AUTOSAR XML (schema 00045)
package /Cpr
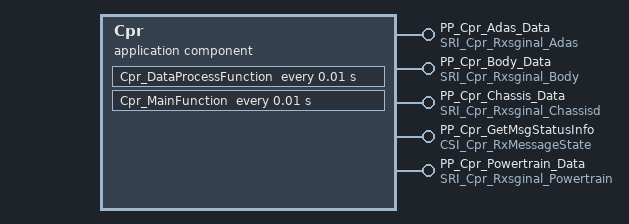
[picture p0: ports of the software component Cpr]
  application sw component type Cpr
    5 x provide port:
      PP_Cpr_Adas_Data: provided-interface=SRI_Cpr_Rxsginal_Adas
      PP_Cpr_Body_Data: provided-interface=SRI_Cpr_Rxsginal_Body
      PP_Cpr_Chassis_Data: provided-interface=SRI_Cpr_Rxsginal_Chassisd
      PP_Cpr_GetMsgStatusInfo: provided-interface=CSI_Cpr_RxMessageState
      PP_Cpr_Powertrain_Data: provided-interface=SRI_Cpr_Rxsginal_Powertrain
    behavior Cpr_IB: handle-termination-and-restart=NO-SUPPORT
      operation invoked event Get_RxMsgStatus_Event: start-on-event=Get_RxMsgStatus, operation=PP_Cpr_GetMsgStatusInfo.Get_RxMsgStatus
      init event InitEvent_Cpr_InitFunction: start-on-event=Cpr_InitFunction
      timing event TimingEvent_Cpr_DataProcessFunction: start-on-event=Cpr_DataProcessFunction, period=0.01
      timing event TimingEvent_Cpr_MainFunction: start-on-event=Cpr_MainFunction, period=0.01
      4 x runnable:
        Cpr_DataProcessFunction
        Cpr_InitFunction
        Cpr_MainFunction
          data-send-points:
            252 x access:
              dsp_ACCMode: accessed-variable=PP_Cpr_Adas_Data.ACCMode
              dsp_ACCMode_Status: accessed-variable=PP_Cpr_Adas_Data.ACCMode_Status
              dsp_ACC_HostLaneLeftStatus: accessed-variable=PP_Cpr_Body_Data.ACC_HostLaneLeftStatus
              dsp_ACC_HostLaneRightStatus: accessed-variable=PP_Cpr_Body_Data.ACC_HostLaneRightStatus
              dsp_ACC_IACCHWAMode: accessed-variable=PP_Cpr_Body_Data.AccIaccHWAMode
              dsp_AccIaccHWAMode_Status: accessed-variable=PP_Cpr_Body_Data.AccIaccHWAMode_Status
              dsp_AdsUDLCStatus: accessed-variable=PP_Cpr_Chassis_Data.AdsUDLCStatus
              dsp_AdsUDLCStatus_Status: accessed-variable=PP_Cpr_Chassis_Data.AdsUDLCStatus_Status
              dsp_BCM_BrakeLampError: accessed-variable=PP_Cpr_Body_Data.BCM_BrakeLampError
              dsp_BCM_BrakeLampError_Status: accessed-variable=PP_Cpr_Body_Data.BCM_BrakeLampError_Status
              dsp_BCM_TurnLightSwitchSts: accessed-variable=PP_Cpr_Body_Data.BCM_TurnLightSwitchSts
              dsp_BCM_TurnLightSwitchSts_S: accessed-variable=PP_Cpr_Body_Data.BCM_TurnLightSwitchSts_Status
              dsp_BcmAutHeadLiSts: accessed-variable=PP_Cpr_Body_Data.BcmAutHeadLiSts
              dsp_BcmAutHeadLiSts_Status: accessed-variable=PP_Cpr_Body_Data.BcmAutHeadLiSts_Status
              dsp_BcmDrvrDoorSts: accessed-variable=PP_Cpr_Body_Data.BcmDrvrDoorSts
              dsp_BcmDrvrDoorSts_Status: accessed-variable=PP_Cpr_Body_Data.BcmDrvrDoorSts_Status
              dsp_BcmEmgyLiSts: accessed-variable=PP_Cpr_Body_Data.BcmEmgyLiSts
              dsp_BcmEmgyLiSts_Status: accessed-variable=PP_Cpr_Body_Data.BcmEmgyLiSts_Status
              dsp_BcmFrntFogLmpSts: accessed-variable=PP_Cpr_Body_Data.BcmFrntFogLmpSts
              dsp_BcmFrntFogLmpSts_Status: accessed-variable=PP_Cpr_Body_Data.BcmFrntFogLmpSts_Status
              dsp_BcmFrntWiperSts: accessed-variable=PP_Cpr_Body_Data.BcmFrntWiperSts
              dsp_BcmFrntWiperSts_Status: accessed-variable=PP_Cpr_Body_Data.BcmFrntWiperSts_Status
              dsp_BcmHiBeamSts: accessed-variable=PP_Cpr_Body_Data.BcmHiBeamSts
              dsp_BcmHiBeamSts_Status: accessed-variable=PP_Cpr_Body_Data.BcmHiBeamSts_Status
              dsp_BcmLeReDoorSts: accessed-variable=PP_Cpr_Body_Data.BcmLeReDoorSts
              dsp_BcmLeReDoorSts_Status: accessed-variable=PP_Cpr_Body_Data.BcmLeReDoorSts_Status
              dsp_BcmLoBeamSts: accessed-variable=PP_Cpr_Body_Data.BcmLoBeamSts
              dsp_BcmLoBeamSts_Status: accessed-variable=PP_Cpr_Body_Data.BcmLoBeamSts_Status
              dsp_BcmPassDoorSts: accessed-variable=PP_Cpr_Body_Data.BcmPassDoorSts
              dsp_BcmPassDoorSts_Status: accessed-variable=PP_Cpr_Body_Data.BcmPassDoorSts_Status
              dsp_BcmReFoglmpSts: accessed-variable=PP_Cpr_Body_Data.BcmReFoglmpSts
              dsp_BcmReFoglmpSts_Status: accessed-variable=PP_Cpr_Body_Data.BcmReFoglmpSts_Status
              dsp_BcmRiReDoorSts: accessed-variable=PP_Cpr_Body_Data.BcmRiReDoorSts
              dsp_BcmRiReDoorSts_Status: accessed-variable=PP_Cpr_Body_Data.BcmRiReDoorSts_Status
              dsp_BcmTurnIndcrLe: accessed-variable=PP_Cpr_Body_Data.BcmTurnIndcrLe
              dsp_BcmTurnIndcrLe_Status: accessed-variable=PP_Cpr_Body_Data.BcmTurnIndcrLe_Status
              dsp_BcmTurnIndcrRi: accessed-variable=PP_Cpr_Body_Data.BcmTurnIndcrRi
              dsp_BcmTurnIndcrRi_Status: accessed-variable=PP_Cpr_Body_Data.BcmTurnIndcrRi_Status
              dsp_BrakePressureSimulator: accessed-variable=PP_Cpr_Chassis_Data.BrakePressureSimulator
              dsp_BrakePressureSimulator_S: accessed-variable=PP_Cpr_Chassis_Data.BrakePressureSimulator_Status
              dsp_EPS_APA_EpasFAILED: accessed-variable=PP_Cpr_Chassis_Data.EPS_APA_EpasFAILED
              dsp_EPS_APA_EpasFAILED_Status: accessed-variable=PP_Cpr_Chassis_Data.EPS_APA_EpasFAILED_Status
              dsp_EPS_ActualMotorTorq: accessed-variable=PP_Cpr_Chassis_Data.EPS_ActualMotorTorq
              dsp_EPS_ActualMotorTorq_Stat: accessed-variable=PP_Cpr_Chassis_Data.EPS_ActualMotorTorq_Status
              dsp_EPS_ActualTorsionBarTorq: accessed-variable=PP_Cpr_Chassis_Data.EPS_ActualTorsionBarTorq
              dsp_EPS_ActualTorsionBarTorq0: accessed-variable=PP_Cpr_Chassis_Data.EPS_ActualTorsionBarTorq_Status
              dsp_EPS_MeasuredTorsionBarTo: accessed-variable=PP_Cpr_Chassis_Data.EPS_MeasuredTorsionBarTorqValid
              dsp_EPS_Pinionang_Vali: accessed-variable=PP_Cpr_Chassis_Data.EPS_Pinionang_Valid
              dsp_EPS_fault_state: accessed-variable=PP_Cpr_Chassis_Data.EPS_fault_state
              dsp_EPS_fault_state_Status: accessed-variable=PP_Cpr_Chassis_Data.EPS_fault_state_Status
              dsp_ESP_LatAccelValid: accessed-variable=PP_Cpr_Chassis_Data.ESP_LatAccelValid
              dsp_ESP_LongAccelValid: accessed-variable=PP_Cpr_Chassis_Data.ESP_LongAccelValid
              dsp_ESP_YawRateValid: accessed-variable=PP_Cpr_Chassis_Data.ESP_YawRateValid
              dsp_EpsConcussAvailabilitySt: accessed-variable=PP_Cpr_Chassis_Data.EpsConcussAvailabilityStatus
              dsp_EpsConcussAvailabilitySt0: accessed-variable=PP_Cpr_Chassis_Data.EpsConcussAvailabilityStatus_Status
              dsp_EpsFaild: accessed-variable=PP_Cpr_Chassis_Data.EpsFaild
              dsp_EpsFaild_Status: accessed-variable=PP_Cpr_Chassis_Data.EpsFaild_Status
              dsp_EpsIACCabortreason: accessed-variable=PP_Cpr_Chassis_Data.EpsIACCabortreason
              dsp_EpsIACCabortreason_Status: accessed-variable=PP_Cpr_Chassis_Data.EpsIACCabortreason_Status
              dsp_EpsLatCtrlActive: accessed-variable=PP_Cpr_Chassis_Data.EpsLatCtrlActive
              dsp_EpsLatCtrlActive_Status: accessed-variable=PP_Cpr_Chassis_Data.EpsLatCtrlActive_Status
              dsp_EpsLatCtrlAvailabilitySt: accessed-variable=PP_Cpr_Chassis_Data.EpsLatCtrlAvailabilityStatus
              dsp_EpsLatCtrlAvailabilitySt0: accessed-variable=PP_Cpr_Chassis_Data.EpsLatCtrlAvailabilityStatus_Status
              dsp_EpsMeasuredTorsionBarTor: accessed-variable=PP_Cpr_Chassis_Data.EpsMeasuredTorsionBarTorque
              dsp_EpsMeasuredTorsionBarTor0: accessed-variable=PP_Cpr_Chassis_Data.EpsMeasuredTorsionBarTorq_Status
              dsp_EpsMeasuredTorsionBarTor1: accessed-variable=PP_Cpr_Chassis_Data.EpsMeasuredTorsionBarTorque_Status
              dsp_EpsPinionang: accessed-variable=PP_Cpr_Chassis_Data.EpsPinionang
              dsp_EpsPinionang_Status: accessed-variable=PP_Cpr_Chassis_Data.EpsPinionang_Status
              dsp_EpsSasCalSts: accessed-variable=PP_Cpr_Chassis_Data.EpsSasCalSts
              dsp_EpsSasCalSts_Status: accessed-variable=PP_Cpr_Chassis_Data.EpsSasCalSts_Status
              dsp_EpsSasSteerAg: accessed-variable=PP_Cpr_Chassis_Data.EpsSasSteerAg
              dsp_EpsSasSteerAgVld: accessed-variable=PP_Cpr_Chassis_Data.EpsSasSteerAgVld
              dsp_EpsSasSteerAg_Status: accessed-variable=PP_Cpr_Chassis_Data.EpsSasSteerAg_Status
              dsp_EpsSteerAgRate: accessed-variable=PP_Cpr_Chassis_Data.EpsSteerAgRate
              dsp_EpsSteerAgRate_Status: accessed-variable=PP_Cpr_Chassis_Data.EpsSteerAgRate_Status
              dsp_EpsSteerAgSensFilr: accessed-variable=PP_Cpr_Chassis_Data.EpsSteerAgSensFilr
              dsp_EpsSteerAgSensFilr_Status: accessed-variable=PP_Cpr_Chassis_Data.EpsSteerAgSensFilr_Status
              dsp_EspABAactive: accessed-variable=PP_Cpr_Chassis_Data.EspABAactive
              dsp_EspABAactive_Status: accessed-variable=PP_Cpr_Chassis_Data.EspABAactive_Status
              dsp_EspABAavailable: accessed-variable=PP_Cpr_Chassis_Data.EspABAavailable
              dsp_EspABAavailable_Status: accessed-variable=PP_Cpr_Chassis_Data.EspABAavailable_Status
              dsp_EspAEBAvailable: accessed-variable=PP_Cpr_Chassis_Data.EspAEBAvailable
              dsp_EspAEBAvailable_Status: accessed-variable=PP_Cpr_Chassis_Data.EspAEBAvailable_Status
              dsp_EspAEBdecActive: accessed-variable=PP_Cpr_Chassis_Data.EspAEBdecActive
              dsp_EspAEBdecActive_Status: accessed-variable=PP_Cpr_Chassis_Data.EspAEBdecActive_Status
              dsp_EspAWBactive: accessed-variable=PP_Cpr_Chassis_Data.EspAWBactive
              dsp_EspAWBactive_Status: accessed-variable=PP_Cpr_Chassis_Data.EspAWBactive_Status
              dsp_EspAWBavailable: accessed-variable=PP_Cpr_Chassis_Data.EspAWBavailable
              dsp_EspAWBavailable_Status: accessed-variable=PP_Cpr_Chassis_Data.EspAWBavailable_Status
              dsp_EspAbsActv: accessed-variable=PP_Cpr_Chassis_Data.EspAbsActv
              dsp_EspAbsActv_Status: accessed-variable=PP_Cpr_Chassis_Data.EspAbsActv_Status
              dsp_EspAbsFailr: accessed-variable=PP_Cpr_Chassis_Data.EspAbsFailr
              dsp_EspAbsFailr_Status: accessed-variable=PP_Cpr_Chassis_Data.EspAbsFailr_Status
              dsp_EspActvSts: accessed-variable=PP_Cpr_Chassis_Data.EspActvSts
              dsp_EspActvSts_Status: accessed-variable=PP_Cpr_Chassis_Data.EspActvSts_Status
              dsp_EspEbdFailr: accessed-variable=PP_Cpr_Chassis_Data.EspEbdFailr
              dsp_EspEbdFailr_Status: accessed-variable=PP_Cpr_Chassis_Data.EspEbdFailr_Status
              dsp_EspLatAccel: accessed-variable=PP_Cpr_Chassis_Data.EspLatAccel
              dsp_EspLatAccel_Status: accessed-variable=PP_Cpr_Chassis_Data.EspLatAccel_Status
              dsp_EspLongAccel: accessed-variable=PP_Cpr_Chassis_Data.EspLongAccel
              dsp_EspLongAccel_Status: accessed-variable=PP_Cpr_Chassis_Data.EspLongAccel_Status
              dsp_EspPrefillActive: accessed-variable=PP_Cpr_Chassis_Data.EspPrefillActive
              dsp_EspPrefillActive_Status: accessed-variable=PP_Cpr_Chassis_Data.EspPrefillActive_Status
              dsp_EspPrefillAvailable: accessed-variable=PP_Cpr_Chassis_Data.EspPrefillAvailable
              dsp_EspPrefillAvailable_Stat: accessed-variable=PP_Cpr_Chassis_Data.EspPrefillAvailable_Status
              dsp_EspTcsActvSts: accessed-variable=PP_Cpr_Chassis_Data.EspTcsActvSts
              dsp_EspTcsActvSts_Status: accessed-variable=PP_Cpr_Chassis_Data.EspTcsActvSts_Status
              dsp_EspTcsFailr: accessed-variable=PP_Cpr_Chassis_Data.EspTcsFailr
              dsp_EspTcsFailr_Status: accessed-variable=PP_Cpr_Chassis_Data.EspTcsFailr_Status
              dsp_EspVdcActvSts: accessed-variable=PP_Cpr_Chassis_Data.EspVdcActvSts
              dsp_EspVdcActvSts_Status: accessed-variable=PP_Cpr_Chassis_Data.EspVdcActvSts_Status
              dsp_EspVehSpd: accessed-variable=PP_Cpr_Chassis_Data.EspVehSpd
              dsp_EspVehSpdVld: accessed-variable=PP_Cpr_Chassis_Data.EspVehSpdVld
              dsp_EspVehSpd_Status: accessed-variable=PP_Cpr_Chassis_Data.EspVehSpd_Status
              dsp_EspYawRate: accessed-variable=PP_Cpr_Chassis_Data.EspYawRate
              dsp_EspYawRate_Status: accessed-variable=PP_Cpr_Chassis_Data.EspYawRate_Status
              dsp_FR_RadarFailureStatus: accessed-variable=PP_Cpr_Adas_Data.FR_RadarFailureStatus
              dsp_FR_RadarFailureStatus_St: accessed-variable=PP_Cpr_Adas_Data.FR_RadarFailureStatus_Status
              dsp_FRadarCalibrationStatus: accessed-variable=PP_Cpr_Adas_Data.FRadarCalibrationStatus
              dsp_FRadarCalibrationStatus_: accessed-variable=PP_Cpr_Adas_Data.FRadarCalibrationStatus_Status
              dsp_IBCU_PFSBrakePressureVal: accessed-variable=PP_Cpr_Chassis_Data.IBCU_PFSBrakePressureValid
              dsp_IP_DISFail: accessed-variable=PP_Cpr_Body_Data.IP_DISFail
              dsp_IP_DISFail_Status: accessed-variable=PP_Cpr_Body_Data.IP_DISFail_Status
              dsp_IP_QDashACCFail: accessed-variable=PP_Cpr_Body_Data.IP_QDashACCFail
              dsp_IP_QDashACCFail_Status: accessed-variable=PP_Cpr_Body_Data.IP_QDashACCFail_Status
              dsp_IbBrkPedlStsGb: accessed-variable=PP_Cpr_Chassis_Data.IbBrkPedlStsGb
              dsp_IbBrkPedlStsGbVld: accessed-variable=PP_Cpr_Chassis_Data.IbBrkPedlStsGbVld
              dsp_IbBrkPedlStsGb_Status: accessed-variable=PP_Cpr_Chassis_Data.IbBrkPedlStsGb_Status
              dsp_IbBrkPedlTrvlDrvr: accessed-variable=PP_Cpr_Chassis_Data.IbBrkPedlTrvlDrvr
              dsp_IbBrkPedlTrvlDrvrVld: accessed-variable=PP_Cpr_Chassis_Data.IbBrkPedlTrvlDrvrVld
              dsp_PlungerBrakePressure: accessed-variable=PP_Cpr_Chassis_Data.PlungerBrakePressure
              dsp_PlungerBrakePressure_Sta: accessed-variable=PP_Cpr_Chassis_Data.PlungerBrakePressure_Status
              dsp_RadarObj1_Dx: accessed-variable=PP_Cpr_Adas_Data.RadarObj1_Dx
              dsp_RadarObj1_Dx_Status: accessed-variable=PP_Cpr_Adas_Data.RadarObj1_Dx_Status
              dsp_RadarObj1_Dy: accessed-variable=PP_Cpr_Adas_Data.RadarObj1_Dy
              dsp_RadarObj1_Dy_Status: accessed-variable=PP_Cpr_Adas_Data.RadarObj1_Dy_Status
              dsp_RadarObj1_ExistProb: accessed-variable=PP_Cpr_Adas_Data.RadarObj1_ExistProb
              dsp_RadarObj1_ExistProb_Stat: accessed-variable=PP_Cpr_Adas_Data.RadarObj1_ExistProb_Status
              dsp_RadarObj1_Length: accessed-variable=PP_Cpr_Adas_Data.RadarObj1_Length
              dsp_RadarObj1_Length_Status: accessed-variable=PP_Cpr_Adas_Data.RadarObj1_Length_Status
              dsp_RadarObj1_Location: accessed-variable=PP_Cpr_Adas_Data.RadarObj1_Location
              dsp_RadarObj1_Location_Status: accessed-variable=PP_Cpr_Adas_Data.RadarObj1_Location_Status
              dsp_RadarObj1_Measured: accessed-variable=PP_Cpr_Adas_Data.RadarObj1_Measured
              dsp_RadarObj1_Measured_Status: accessed-variable=PP_Cpr_Adas_Data.RadarObj1_Measured_Status
              dsp_RadarObj1_RelAx: accessed-variable=PP_Cpr_Adas_Data.RadarObj1_RelAx
              dsp_RadarObj1_RelAx_Status: accessed-variable=PP_Cpr_Adas_Data.RadarObj1_RelAx_Status
              dsp_RadarObj1_RelVx: accessed-variable=PP_Cpr_Adas_Data.RadarObj1_RelVx
              dsp_RadarObj1_RelVx_Status: accessed-variable=PP_Cpr_Adas_Data.RadarObj1_RelVx_Status
              dsp_RadarObj1_RelVy: accessed-variable=PP_Cpr_Adas_Data.RadarObj1_RelVy
              dsp_RadarObj1_RelVy_Status: accessed-variable=PP_Cpr_Adas_Data.RadarObj1_RelVy_Status
              dsp_RadarObj1_Width: accessed-variable=PP_Cpr_Adas_Data.RadarObj1_Width
              dsp_RadarObj1_Width_Status: accessed-variable=PP_Cpr_Adas_Data.RadarObj1_Width_Status
              dsp_RadarObj2_Dx: accessed-variable=PP_Cpr_Adas_Data.RadarObj2_Dx
              dsp_RadarObj2_Dx_Status: accessed-variable=PP_Cpr_Adas_Data.RadarObj2_Dx_Status
              dsp_RadarObj2_Dy: accessed-variable=PP_Cpr_Adas_Data.RadarObj2_Dy
              dsp_RadarObj2_Dy_Status: accessed-variable=PP_Cpr_Adas_Data.RadarObj2_Dy_Status
              dsp_RadarObj2_ExistProb: accessed-variable=PP_Cpr_Adas_Data.RadarObj2_ExistProb
              dsp_RadarObj2_ExistProb_Stat: accessed-variable=PP_Cpr_Adas_Data.RadarObj2_ExistProb_Status
              dsp_RadarObj2_Length: accessed-variable=PP_Cpr_Adas_Data.RadarObj2_Length
              dsp_RadarObj2_Length_Status: accessed-variable=PP_Cpr_Adas_Data.RadarObj2_Length_Status
              dsp_RadarObj2_Location: accessed-variable=PP_Cpr_Adas_Data.RadarObj2_Location
              dsp_RadarObj2_Location_Status: accessed-variable=PP_Cpr_Adas_Data.RadarObj2_Location_Status
              dsp_RadarObj2_Measured: accessed-variable=PP_Cpr_Adas_Data.RadarObj2_Measured
              dsp_RadarObj2_Measured_Status: accessed-variable=PP_Cpr_Adas_Data.RadarObj2_Measured_Status
              dsp_RadarObj2_RelAx: accessed-variable=PP_Cpr_Adas_Data.RadarObj2_RelAx
              dsp_RadarObj2_RelAx_Status: accessed-variable=PP_Cpr_Adas_Data.RadarObj2_RelAx_Status
              dsp_RadarObj2_RelVx: accessed-variable=PP_Cpr_Adas_Data.RadarObj2_RelVx
              dsp_RadarObj2_RelVx_Status: accessed-variable=PP_Cpr_Adas_Data.RadarObj2_RelVx_Status
              dsp_RadarObj2_RelVy: accessed-variable=PP_Cpr_Adas_Data.RadarObj2_RelVy
              dsp_RadarObj2_RelVy_Status: accessed-variable=PP_Cpr_Adas_Data.RadarObj2_RelVy_Status
              dsp_RadarObj2_Width: accessed-variable=PP_Cpr_Adas_Data.RadarObj2_Width
              dsp_RadarObj2_Width_Status: accessed-variable=PP_Cpr_Adas_Data.RadarObj2_Width_Status
              dsp_RadarObj3_Dx: accessed-variable=PP_Cpr_Adas_Data.RadarObj3_Dx
              dsp_RadarObj3_Dx_Status: accessed-variable=PP_Cpr_Adas_Data.RadarObj3_Dx_Status
              dsp_RadarObj3_Dy: accessed-variable=PP_Cpr_Adas_Data.RadarObj3_Dy
              dsp_RadarObj3_Dy_Status: accessed-variable=PP_Cpr_Adas_Data.RadarObj3_Dy_Status
              dsp_RadarObj3_ExistProb: accessed-variable=PP_Cpr_Adas_Data.RadarObj3_ExistProb
              dsp_RadarObj3_ExistProb_Stat: accessed-variable=PP_Cpr_Adas_Data.RadarObj3_ExistProb_Status
              dsp_RadarObj3_Length: accessed-variable=PP_Cpr_Adas_Data.RadarObj3_Length
              dsp_RadarObj3_Length_Status: accessed-variable=PP_Cpr_Adas_Data.RadarObj3_Length_Status
              dsp_RadarObj3_Location: accessed-variable=PP_Cpr_Adas_Data.RadarObj3_Location
              dsp_RadarObj3_Location_Status: accessed-variable=PP_Cpr_Adas_Data.RadarObj3_Location_Status
              dsp_RadarObj3_Measured: accessed-variable=PP_Cpr_Adas_Data.RadarObj3_Measured
              dsp_RadarObj3_Measured_Status: accessed-variable=PP_Cpr_Adas_Data.RadarObj3_Measured_Status
              dsp_RadarObj3_RelAx: accessed-variable=PP_Cpr_Adas_Data.RadarObj3_RelAx
              dsp_RadarObj3_RelAx_Status: accessed-variable=PP_Cpr_Adas_Data.RadarObj3_RelAx_Status
              dsp_RadarObj3_RelVx: accessed-variable=PP_Cpr_Adas_Data.RadarObj3_RelVx
              dsp_RadarObj3_RelVx_Status: accessed-variable=PP_Cpr_Adas_Data.RadarObj3_RelVx_Status
              dsp_RadarObj3_RelVy: accessed-variable=PP_Cpr_Adas_Data.RadarObj3_RelVy
              dsp_RadarObj3_RelVy_Status: accessed-variable=PP_Cpr_Adas_Data.RadarObj3_RelVy_Status
              dsp_RadarObj3_Width: accessed-variable=PP_Cpr_Adas_Data.RadarObj3_Width
              dsp_RadarObj3_Width_Status: accessed-variable=PP_Cpr_Adas_Data.RadarObj3_Width_Status
              dsp_RadarObj4_Dx: accessed-variable=PP_Cpr_Adas_Data.RadarObj4_Dx
              dsp_RadarObj4_Dx_Status: accessed-variable=PP_Cpr_Adas_Data.RadarObj4_Dx_Status
              dsp_RadarObj4_Dy: accessed-variable=PP_Cpr_Adas_Data.RadarObj4_Dy
              dsp_RadarObj4_Dy_Status: accessed-variable=PP_Cpr_Adas_Data.RadarObj4_Dy_Status
              dsp_RadarObj4_ExistProb: accessed-variable=PP_Cpr_Adas_Data.RadarObj4_ExistProb
              dsp_RadarObj4_ExistProb_Stat: accessed-variable=PP_Cpr_Adas_Data.RadarObj4_ExistProb_Status
              dsp_RadarObj4_Length: accessed-variable=PP_Cpr_Adas_Data.RadarObj4_Length
              dsp_RadarObj4_Length_Status: accessed-variable=PP_Cpr_Adas_Data.RadarObj4_Length_Status
              dsp_RadarObj4_Location: accessed-variable=PP_Cpr_Adas_Data.RadarObj4_Location
              dsp_RadarObj4_Location_Status: accessed-variable=PP_Cpr_Adas_Data.RadarObj4_Location_Status
              dsp_RadarObj4_Measured: accessed-variable=PP_Cpr_Adas_Data.RadarObj4_Measured
              dsp_RadarObj4_Measured_Status: accessed-variable=PP_Cpr_Adas_Data.RadarObj4_Measured_Status
              dsp_RadarObj4_RelAx: accessed-variable=PP_Cpr_Adas_Data.RadarObj4_RelAx
              dsp_RadarObj4_RelAx_Status: accessed-variable=PP_Cpr_Adas_Data.RadarObj4_RelAx_Status
              dsp_RadarObj4_RelVx: accessed-variable=PP_Cpr_Adas_Data.RadarObj4_RelVx
              dsp_RadarObj4_RelVx_Status: accessed-variable=PP_Cpr_Adas_Data.RadarObj4_RelVx_Status
              dsp_RadarObj4_RelVy: accessed-variable=PP_Cpr_Adas_Data.RadarObj4_RelVy
              dsp_RadarObj4_RelVy_Status: accessed-variable=PP_Cpr_Adas_Data.RadarObj4_RelVy_Status
              dsp_RadarObj4_Width: accessed-variable=PP_Cpr_Adas_Data.RadarObj4_Width
              dsp_RadarObj4_Width_Status: accessed-variable=PP_Cpr_Adas_Data.RadarObj4_Width_Status
              dsp_SrsDrvrBucSwtSts: accessed-variable=PP_Cpr_Body_Data.SrsDrvrBucSwtSts
              dsp_SrsDrvrBucSwtSts_Status: accessed-variable=PP_Cpr_Body_Data.SrsDrvrBucSwtSts_Status
              dsp_SrsPassBucSwtSts: accessed-variable=PP_Cpr_Body_Data.SrsPassBucSwtSts
              dsp_SrsPassBucSwtSts_Status: accessed-variable=PP_Cpr_Body_Data.SrsPassBucSwtSts_Status
              dsp_TmsFrntBlowMod: accessed-variable=PP_Cpr_Body_Data.TmsFrntBlowMod
              dsp_TmsFrntBlowMod_Status: accessed-variable=PP_Cpr_Body_Data.TmsFrntBlowMod_Status
              dsp_VcuAccrPedlPosn: accessed-variable=PP_Cpr_Chassis_Data.VcuAccrPedlPosn
              dsp_VcuAccrPedlPosnVld: accessed-variable=PP_Cpr_Chassis_Data.VcuAccrPedlPosnVld
              dsp_VcuAccrPedlPosn_Status: accessed-variable=PP_Cpr_Chassis_Data.VcuAccrPedlPosn_Status
              dsp_VcuGearPosn: accessed-variable=PP_Cpr_Chassis_Data.VcuGearPosn
              dsp_VcuGearPosn_Status: accessed-variable=PP_Cpr_Chassis_Data.VcuGearPosn_Status
              dsp_VcuVehGearPosnVld: accessed-variable=PP_Cpr_Chassis_Data.VcuVehGearPosnVld
              dsp_WhlSpdFrntLePls: accessed-variable=PP_Cpr_Powertrain_Data.WhlSpdFrntLePls
              dsp_WhlSpdFrntLePls_Status: accessed-variable=PP_Cpr_Powertrain_Data.WhlSpdFrntLePls_Status
              dsp_WhlSpdFrntRiPls: accessed-variable=PP_Cpr_Powertrain_Data.WhlSpdFrntRiPls
              dsp_WhlSpdFrntRiPls_Status: accessed-variable=PP_Cpr_Powertrain_Data.WhlSpdFrntRiPls_Status
              dsp_WhlSpdLeFrntData: accessed-variable=PP_Cpr_Powertrain_Data.WhlSpdLeFrntData
              dsp_WhlSpdLeFrntDataVld: accessed-variable=PP_Cpr_Powertrain_Data.WhlSpdLeFrntDataVld
              dsp_WhlSpdLeFrntData_Status: accessed-variable=PP_Cpr_Powertrain_Data.WhlSpdLeFrntData_Status
              dsp_WhlSpdLeFrntDir: accessed-variable=PP_Cpr_Powertrain_Data.WhlSpdLeFrntDir
              dsp_WhlSpdLeFrntDir_Status: accessed-variable=PP_Cpr_Powertrain_Data.WhlSpdLeFrntDir_Status
              dsp_WhlSpdLeReData: accessed-variable=PP_Cpr_Powertrain_Data.WhlSpdLeReData
              dsp_WhlSpdLeReDataVld: accessed-variable=PP_Cpr_Powertrain_Data.WhlSpdLeReDataVld
              dsp_WhlSpdLeReData_Status: accessed-variable=PP_Cpr_Powertrain_Data.WhlSpdLeReData_Status
              dsp_WhlSpdLeReDir: accessed-variable=PP_Cpr_Powertrain_Data.WhlSpdLeReDir
              dsp_WhlSpdLeReDir_Status: accessed-variable=PP_Cpr_Powertrain_Data.WhlSpdLeReDir_Status
              dsp_WhlSpdReLePls: accessed-variable=PP_Cpr_Powertrain_Data.WhlSpdReLePls
              dsp_WhlSpdReLePls_Status: accessed-variable=PP_Cpr_Powertrain_Data.WhlSpdReLePls_Status
              dsp_WhlSpdReRiPls: accessed-variable=PP_Cpr_Powertrain_Data.WhlSpdReRiPls
              dsp_WhlSpdReRiPls_Status: accessed-variable=PP_Cpr_Powertrain_Data.WhlSpdReRiPls_Status
              dsp_WhlSpdRiFrntData: accessed-variable=PP_Cpr_Powertrain_Data.WhlSpdRiFrntData
              dsp_WhlSpdRiFrntDataVld: accessed-variable=PP_Cpr_Powertrain_Data.WhlSpdRiFrntDataVld
              dsp_WhlSpdRiFrntData_Status: accessed-variable=PP_Cpr_Powertrain_Data.WhlSpdRiFrntData_Status
              dsp_WhlSpdRiFrntDir: accessed-variable=PP_Cpr_Powertrain_Data.WhlSpdRiFrntDir
              dsp_WhlSpdRiFrntDir_Status: accessed-variable=PP_Cpr_Powertrain_Data.WhlSpdRiFrntDir_Status
              dsp_WhlSpdRiReData: accessed-variable=PP_Cpr_Powertrain_Data.WhlSpdRiReData
              dsp_WhlSpdRiReDataVld: accessed-variable=PP_Cpr_Powertrain_Data.WhlSpdRiReDataVld
              dsp_WhlSpdRiReData_Status: accessed-variable=PP_Cpr_Powertrain_Data.WhlSpdRiReData_Status
              dsp_WhlSpdRiReDir: accessed-variable=PP_Cpr_Powertrain_Data.WhlSpdRiReDir
              dsp_WhlSpdRiReDir_Status: accessed-variable=PP_Cpr_Powertrain_Data.WhlSpdRiReDir_Status
        Get_RxMsgStatus
  swc implementation CprImpl: programming-language=C, sw-version=0.0.1, vendor-id=0, behavior=Cpr_IB
    code-descriptors:
      code CodeGen: artifact-descriptors=[{short-label=SWSRC, category=SWSRC}, {short-label=SWHDR, category=SWHDR}]
    resource consumption Resource
      memory section CODE: sw-addrmethod=CODE
      memory section VAR_UNSPECIFIED: sw-addrmethod=VAR
